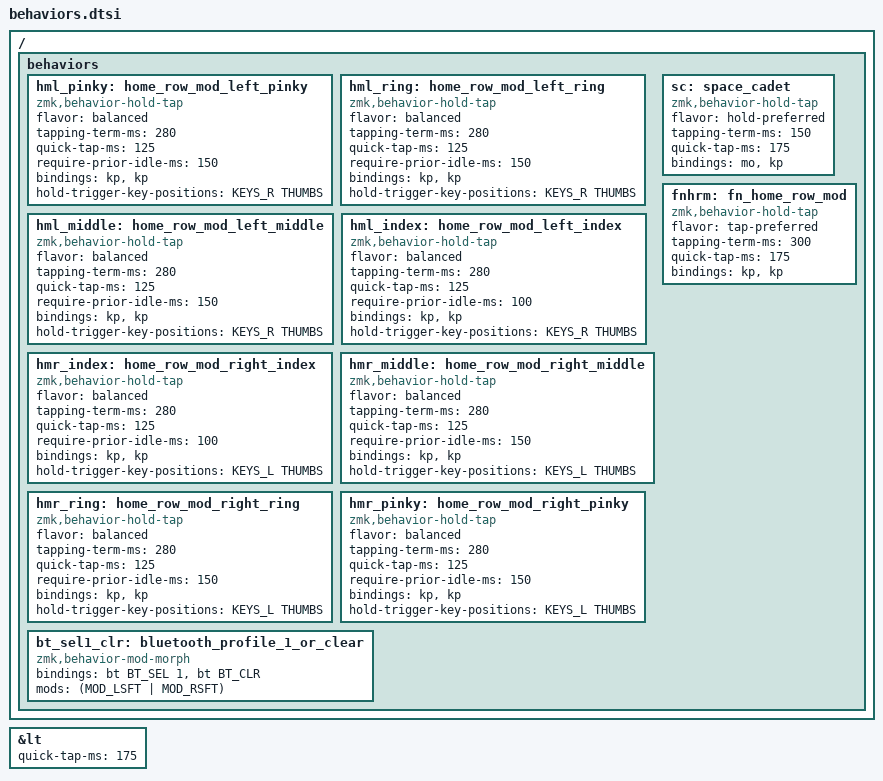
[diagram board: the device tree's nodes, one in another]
#include <behaviors.dtsi>

// Key positions per hand, used for positional (bilateral) home row mods.
// Left-hand keys trigger holds only when followed by a right-hand key or
// thumb, and vice versa, which prevents accidental mods during same-hand
// rolls. Mirrors the go60 keymap's approach, sized for dokodemo's 34 keys.
#define KEYS_L  0  1  2  3  4 10 11 12 13 14 20 21 22 23 24
#define KEYS_R  5  6  7  8  9 15 16 17 18 19 25 26 27 28 29
#define THUMBS 30 31 32 33

/ {
    behaviors {
        // Per-finger home row mods, go60-style: hold for a modifier, tap for
        // the letter. Index fingers use a shorter require-prior-idle-ms since
        // they are the most dexterous and least prone to misfires.
        hml_pinky: home_row_mod_left_pinky {
            compatible = "zmk,behavior-hold-tap";
            #binding-cells = <2>;
            flavor = "balanced";
            tapping-term-ms = <280>;
            quick-tap-ms = <125>;
            require-prior-idle-ms = <150>;
            bindings = <&kp>, <&kp>;
            hold-trigger-key-positions = <KEYS_R THUMBS>;
        };

        hml_ring: home_row_mod_left_ring {
            compatible = "zmk,behavior-hold-tap";
            #binding-cells = <2>;
            flavor = "balanced";
            tapping-term-ms = <280>;
            quick-tap-ms = <125>;
            require-prior-idle-ms = <150>;
            bindings = <&kp>, <&kp>;
            hold-trigger-key-positions = <KEYS_R THUMBS>;
        };

        hml_middle: home_row_mod_left_middle {
            compatible = "zmk,behavior-hold-tap";
            #binding-cells = <2>;
            flavor = "balanced";
            tapping-term-ms = <280>;
            quick-tap-ms = <125>;
            require-prior-idle-ms = <150>;
            bindings = <&kp>, <&kp>;
            hold-trigger-key-positions = <KEYS_R THUMBS>;
        };

        hml_index: home_row_mod_left_index {
            compatible = "zmk,behavior-hold-tap";
            #binding-cells = <2>;
            flavor = "balanced";
            tapping-term-ms = <280>;
            quick-tap-ms = <125>;
            require-prior-idle-ms = <100>;
            bindings = <&kp>, <&kp>;
            hold-trigger-key-positions = <KEYS_R THUMBS>;
        };

        hmr_index: home_row_mod_right_index {
            compatible = "zmk,behavior-hold-tap";
            #binding-cells = <2>;
            flavor = "balanced";
            tapping-term-ms = <280>;
            quick-tap-ms = <125>;
            require-prior-idle-ms = <100>;
            bindings = <&kp>, <&kp>;
            hold-trigger-key-positions = <KEYS_L THUMBS>;
        };

        hmr_middle: home_row_mod_right_middle {
            compatible = "zmk,behavior-hold-tap";
            #binding-cells = <2>;
            flavor = "balanced";
            tapping-term-ms = <280>;
            quick-tap-ms = <125>;
            require-prior-idle-ms = <150>;
            bindings = <&kp>, <&kp>;
            hold-trigger-key-positions = <KEYS_L THUMBS>;
        };

        hmr_ring: home_row_mod_right_ring {
            compatible = "zmk,behavior-hold-tap";
            #binding-cells = <2>;
            flavor = "balanced";
            tapping-term-ms = <280>;
            quick-tap-ms = <125>;
            require-prior-idle-ms = <150>;
            bindings = <&kp>, <&kp>;
            hold-trigger-key-positions = <KEYS_L THUMBS>;
        };

        hmr_pinky: home_row_mod_right_pinky {
            compatible = "zmk,behavior-hold-tap";
            #binding-cells = <2>;
            flavor = "balanced";
            tapping-term-ms = <280>;
            quick-tap-ms = <125>;
            require-prior-idle-ms = <150>;
            bindings = <&kp>, <&kp>;
            hold-trigger-key-positions = <KEYS_L THUMBS>;
        };

        // NavNum thumb keys: tap Delete/Hyper+Space, hold for Fn.
        sc: space_cadet {
            compatible = "zmk,behavior-hold-tap";
            #binding-cells = <2>;
            flavor = "hold-preferred";
            tapping-term-ms = <150>;
            quick-tap-ms = <175>;
            bindings = <&mo>, <&kp>;
        };

        // Fn/media dual-role keys intentionally have no bilateral restriction,
        // allowing Shift+Bluetooth Clear while Fn is held by both thumbs.
        fnhrm: fn_home_row_mod {
            compatible = "zmk,behavior-hold-tap";
            #binding-cells = <2>;
            flavor = "tap-preferred";
            tapping-term-ms = <300>;
            quick-tap-ms = <175>;
            bindings = <&kp>, <&kp>;
        };

        bt_sel1_clr: bluetooth_profile_1_or_clear {
            compatible = "zmk,behavior-mod-morph";
            #binding-cells = <0>;
            bindings = <&bt BT_SEL 1>, <&bt BT_CLR>;
            mods = <(MOD_LSFT | MOD_RSFT)>;
        };
    };
};

// Repeating Space/Backspace should continue to feel like ordinary keys.
&lt { quick-tap-ms = <175>; };
